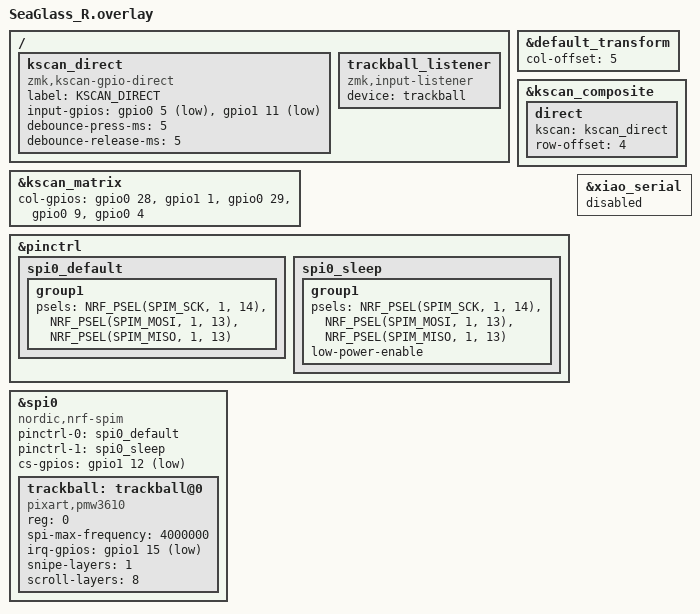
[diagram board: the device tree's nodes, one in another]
#include "SeaGlass.dtsi"

&default_transform {
    col-offset = <5>;
};

/* キーマトリクスの設定 */
&kscan_matrix {
        col-gpios
            = <&gpio0 28 GPIO_ACTIVE_HIGH>
            , <&gpio1 1 GPIO_ACTIVE_HIGH>
            , <&gpio0 29 GPIO_ACTIVE_HIGH>
            , <&gpio0 9 GPIO_ACTIVE_HIGH>
            , <&gpio0 4 GPIO_ACTIVE_HIGH>
            ;
};

/ {
    kscan_direct: kscan_direct {
        compatible = "zmk,kscan-gpio-direct";
        label = "KSCAN_DIRECT";
        input-gpios = 
            <&gpio0 5 (GPIO_ACTIVE_LOW | GPIO_PULL_UP)>,
            <&gpio1 11 (GPIO_ACTIVE_LOW | GPIO_PULL_UP)>
            ;
        debounce-press-ms = <5>;
        debounce-release-ms = <5>;
    };
};

&kscan_composite {
        direct {
            kscan = <&kscan_direct>;
            row-offset = <4>;
    };
};

/* Trackball のリスナー */ 
/ {
    trackball_listener {
        compatible = "zmk,input-listener";
        device = <&trackball>;

    };
};

/* SPI 設定 */
&pinctrl {
    spi0_default: spi0_default {
        group1 {
            psels = <NRF_PSEL(SPIM_SCK, 1, 14)>,
                <NRF_PSEL(SPIM_MOSI, 1, 13)>,
                <NRF_PSEL(SPIM_MISO, 1, 13)>;
        };
    };

    spi0_sleep: spi0_sleep {
        group1 {
            psels = <NRF_PSEL(SPIM_SCK, 1, 14)>,
                <NRF_PSEL(SPIM_MOSI, 1, 13)>,
                <NRF_PSEL(SPIM_MISO, 1, 13)>;
            low-power-enable;
        };
    };
};

/* シリアルを無効化 */
&xiao_serial { status = "disabled"; };

/* SPI デバイス (トラックボール) */
&spi0 {
    status = "okay";
    compatible = "nordic,nrf-spim";
    pinctrl-0 = <&spi0_default>;
    pinctrl-1 = <&spi0_sleep>;
    pinctrl-names = "default", "sleep";
    cs-gpios = <&gpio1 12 GPIO_ACTIVE_LOW>;

    trackball: trackball@0 {
        status = "okay";
        compatible = "pixart,pmw3610";
        reg = <0>;
        spi-max-frequency = <4000000>;
        irq-gpios = <&gpio1 15 (GPIO_ACTIVE_LOW | GPIO_PULL_UP)>;
        snipe-layers = <1>;
        scroll-layers = <8>;
    };
};
